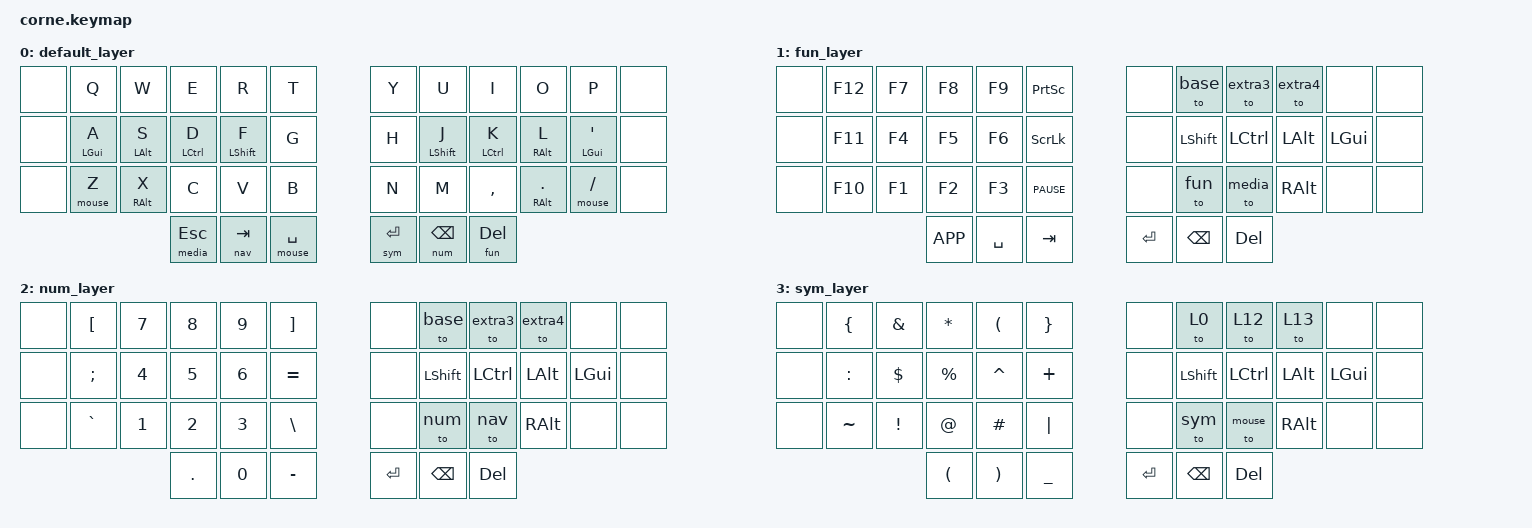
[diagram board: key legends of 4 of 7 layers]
/*
 * Copyright (c) 2020 The ZMK Contributors
 *
 * SPDX-License-Identifier: MIT
 */

#include <behaviors.dtsi>
#include <dt-bindings/zmk/bt.h>
#include <dt-bindings/zmk/keys.h>
#include <dt-bindings/zmk/rgb.h>
#include <dt-bindings/zmk/ext_power.h>
/ {
    behaviors {
        hm: homerow_mods {
            compatible = "zmk,behavior-hold-tap";
            label = "HOMEROW_MODS";
            #binding-cells = <2>;
            tapping-term-ms = <200>;
            quick_tap_ms = <0>;
            flavor = "tap-preferred";
            bindings = <&kp>, <&kp>;

            quick-tap-ms = <180>;
            global-quick-tap;
        };

        ltq: ltq {
            compatible = "zmk,behavior-hold-tap";
            label = "LTQ";
            bindings = <&mo>, <&kp>;

            #binding-cells = <2>;
            tapping-term-ms = <600>;
            global-quick-tap;
            quick-tap-ms = <400>;
        };
    };

    combos {
        compatible = "zmk,combos";

        left_bkt {
            bindings = <&kp LEFT_BRACKET>;
            key-positions = <4 3>;
            timeout-ms = <50>;
        };

        right_bkt {
            bindings = <&kp RBKT>;
            key-positions = <7 8>;
            timeout-ms = <50>;
        };

        left_par {
            bindings = <&kp LEFT_PARENTHESIS>;
            key-positions = <15 16>;
            timeout-ms = <50>;
        };

        right_par {
            bindings = <&kp RIGHT_PARENTHESIS>;
            key-positions = <19 20>;
            timeout-ms = <50>;
        };

        left_brace {
            bindings = <&kp LEFT_BRACE>;
            key-positions = <27 28>;
            timeout-ms = <50>;
        };

        right_brace {
            bindings = <&kp RIGHT_BRACE>;
            key-positions = <32 31>;
            timeout-ms = <50>;
        };

        bac {
            bindings = <&kp BACKSLASH>;
            key-positions = <5 6>;
        };

        pipe {
            bindings = <&kp PIPE>;
            key-positions = <17 18>;
        };
    };
/*
 * ZMK keymap file generated with custom behaviors and multiple layers.
 * Layout: 6 columns per half (12 total per row), 3 keys on bottom row per half
 */

    aliases {
        base  = &default_layer;
        fun   = &fun_layer;
        num   = &num_layer;
        sym   = &sym_layer;
        nav   = &nav_layer;
        mouse = &mouse_layer;
        media = &media_layer;
    };
     behaviors {

    hm: homerow_mods {
      compatible = "zmk,behavior-hold-tap";
      label = "HOMEROW_MODS";
      #binding-cells = <2>;
      tapping-term-ms = <200>;
      quick-tap-ms = <180>;
      flavor = "tap-preferred";
      bindings = <&kp>, <&kp>;
      global-quick-tap;
    };

    ltq: ltq {
      compatible = "zmk,behavior-hold-tap";
      label = "LTQ";
      #binding-cells = <2>;
      tapping-term-ms = <600>;
      quick-tap-ms = <400>;
      flavor = "tap-preferred";
      bindings = <&mo>, <&kp>;
      global-quick-tap;
    };

    caps_word {
      compatible = "zmk,behavior-caps-word";
      label = "CAPS_WORD";
      #binding-cells = <0>;
    };

    rgb_eff {
      compatible = "zmk,behavior-rgb-effect-next";
      label = "RGB_EFF";
      #binding-cells = <0>;
    };

    rgb_hue {
      compatible = "zmk,behavior-rgb-hue-increase";
      label = "RGB_HUE";
      #binding-cells = <0>;
    };

    rgb_sat {
      compatible = "zmk,behavior-rgb-sat-increase";
      label = "RGB_SAT";
      #binding-cells = <0>;
    };

    rgb_bri {
      compatible = "zmk,behavior-rgb-brightness-increase";
      label = "RGB_BRI";
      #binding-cells = <0>;
    };

    rgb_tog {
      compatible = "zmk,behavior-rgb-toggle";
      label = "RGB_TOG";
      #binding-cells = <0>;
    };

    // Mouse Move
    mkp_l {
      compatible = "zmk,behavior-mouse-move";
      label = "MKP_L";
      #binding-cells = <0>;
      move-x = -10;
    };

    mkp_r {
      compatible = "zmk,behavior-mouse-move";
      label = "MKP_R";
      #binding-cells = <0>;
      move-x = 10;
    };

    mkp_u {
      compatible = "zmk,behavior-mouse-move";
      label = "MKP_U";
      #binding-cells = <0>;
      move-y = -10;
    };

    mkp_d {
      compatible = "zmk,behavior-mouse-move";
      label = "MKP_D";
      #binding-cells = <0>;
      move-y = 10;
    };

    // Mouse Scroll
    wkp_l {
      compatible = "zmk,behavior-mouse-scroll";
      label = "WKP_L";
      #binding-cells = <0>;
      scroll-x = -1;
    };

    wkp_r {
      compatible = "zmk,behavior-mouse-scroll";
      label = "WKP_R";
      #binding-cells = <0>;
      scroll-x = 1;
    };

    wkp_u {
      compatible = "zmk,behavior-mouse-scroll";
      label = "WKP_U";
      #binding-cells = <0>;
      scroll-y = 1;
    };

    wkp_d {
      compatible = "zmk,behavior-mouse-scroll";
      label = "WKP_D";
      #binding-cells = <0>;
      scroll-y = -1;
    };

    // Mouse Buttons
    btn1 {
      compatible = "zmk,behavior-mouse-button";
      label = "BTN1";
      #binding-cells = <1>;
      bindings = <0>;
    };

    btn2 {
      compatible = "zmk,behavior-mouse-button";
      label = "BTN2";
      #binding-cells = <1>;
      bindings = <1>;
    };

    btn3 {
      compatible = "zmk,behavior-mouse-button";
      label = "BTN3";
      #binding-cells = <1>;
      bindings = <2>;
    };

    // Bluetooth Select
    bt_sel_0 {
      compatible = "zmk,behavior-bluetooth-select";
      label = "BT_SEL_0";
      #binding-cells = <1>;
      bindings = <0>;
    };

    bt_sel_1 {
      compatible = "zmk,behavior-bluetooth-select";
      label = "BT_SEL_1";
      #binding-cells = <1>;
      bindings = <1>;
    };

    bt_sel_2 {
      compatible = "zmk,behavior-bluetooth-select";
      label = "BT_SEL_2";
      #binding-cells = <1>;
      bindings = <2>;
    };

    bt_sel_3 {
      compatible = "zmk,behavior-bluetooth-select";
      label = "BT_SEL_3";
      #binding-cells = <1>;
      bindings = <3>;
    };

    out_tog {
      compatible = "zmk,behavior-output-toggle";
      label = "OUT_TOG";
      #binding-cells = <0>;
    };

    ep_tog {
      compatible = "zmk,behavior-ext-power-toggle";
      label = "EP_TOG";
      #binding-cells = <0>;
    };
  };

        keymap {
        compatible = "zmk,keymap";

        default_layer {
            bindings = <
                &none          &kp Q           &kp W             &kp E             &kp R             &kp T             &kp Y           &kp U             &kp I             &kp O             &kp P           &none
                &none          &hm LGUI A      &hm LALT S        &hm LCTRL D       &hm LSHFT F       &kp G             &kp H           &hm LSHFT J       &hm LCTRL K       &hm RALT L        &hm LGUI SQT    &none
                &none          &ltq mouse Z          &hm RALT X        &kp C             &kp V             &kp B             &kp N           &kp M             &kp COMMA         &hm RALT DOT      &ltq mouse SLASH      &none
                                             &ltq media ESC           &ltq nav TAB           &ltq mouse SPACE         &ltq sym RET         &ltq num BSPC         &ltq fun DEL
            >;
        };

        fun_layer {
            bindings = <
                &none  &kp F12        &kp F7         &kp F8         &kp F9          &kp PSCRN     &none  &to base         &to extra3        &to extra4        &none          &none
                &none  &kp F11        &kp F4         &kp F5         &kp F6          &kp SLCK      &none  &kp LSHFT     &kp LCTRL     &kp LALT      &kp LGUI       &none
                &none  &kp F10        &kp F1         &kp F2         &kp F3          &kp PAUSE     &none  &to fun        &to media         &kp RALT      &none          &none
                         &kp K_APP      &kp SPACE      &kp TAB         &kp RET        &kp BSPC      &kp DEL
            >;
        };

        num_layer {
            bindings = <
                &none  &kp LBKT       &kp N7         &kp N8         &kp N9         &kp RBKT     &none  &to base         &to extra3        &to extra4        &none          &none
                &none  &kp SEMI       &kp N4         &kp N5         &kp N6         &kp EQUAL    &none  &kp LSHFT     &kp LCTRL     &kp LALT      &kp LGUI       &none
                &none  &kp GRAVE      &kp N1         &kp N2         &kp N3         &kp BSLH     &none  &to num        &to nav         &kp RALT      &none          &none
                         &kp DOT        &kp N0         &kp MINUS      &kp RET        &kp BSPC      &kp DEL
            >;
        };

        sym_layer {
            bindings = <
                &none  &kp LBRC       &kp AMPS       &kp ASTRK      &kp LPAR       &kp RBRC     &none  &to 0         &to 12        &to 13        &none          &none
                &none  &kp COLON      &kp DLLR       &kp PRCNT      &kp CARET      &kp PLUS     &none  &kp LSHFT     &kp LCTRL     &kp LALT      &kp LGUI       &none
                &none  &kp TILDE      &kp EXCL       &kp AT         &kp HASH       &kp PIPE     &none  &to sym         &to mouse         &kp RALT      &none          &none
                         &kp LPAR       &kp RPAR       &kp UNDER      &kp RET        &kp BSPC      &kp DEL
            >;
        };

        mouse_layer {
            bindings = <
                &none  &to 13        &to 12        &to 0         &none         &kp REDO    &kp PASTE   &kp COPY    &kp CUT     &kp UNDO
                &kp LGUI &kp LALT    &kp LCTRL     &kp LSHFT     &none         &mkp_l      &mkp_d      &mkp_u      &mkp_r      &none
                &none  &kp RALT      &to sym         &to mouse         &none         &wkp_l      &wkp_d      &wkp_u      &wkp_r      &none
                         &none        &none         &none         &btn2         &btn1       &btn3
            >;
        };

        nav_layer {
            bindings = <
                &none  &to 13        &to 12        &to 0         &none         &kp REDO     &kp PASTE    &kp COPY     &kp CUT      &kp UNDO
                &kp LGUI &kp LALT    &kp LCTRL     &kp LSHFT     &none         &kp LEFT     &kp DOWN     &kp UP       &kp RIGHT    &caps_word
                &none  &kp RALT      &to 10        &to 7         &none         &kp HOME     &kp PG_DN    &kp PG_UP    &kp END      &kp INS
                         &none        &none         &none         &kp RET       &kp BSPC     &kp DEL
            >;
        };

        media_layer {
            bindings = <
                &none  &to 13        &to 12        &to 0         &none         &rgb_eff     &rgb_hue     &rgb_sat     &rgb_bri     &rgb_tog
                &kp LGUI &kp LALT    &kp LCTRL     &kp LSHFT     &none         &kp C_PREV   &kp C_VOL_DN &kp C_VOL_UP &kp C_NEXT  &ep_tog
                &none  &kp RALT      &to 11        &to 6         &none         &bt_sel_0    &bt_sel_1    &bt_sel_2    &bt_sel_3    &out_tog
                         &none        &none         &none         &kp C_STOP    &kp C_PP     &kp C_MUTE
            >;
        };
    };
};
